# STM32U575 register map
File version: 1.4
CPU: CM33 r0p1, little endian, MPU, FPU, 4 interrupt priority bits
Registers are 32-bit, read-write, reset 0x0 unless marked. A register's access mark holds for its fields unless they carry their own. Offsets are from the block's base; [hi:lo] are bit positions; {n}, {i} and the like mark numbered series.

## ICache
Base 0x40030400
Same registers: SEC_ICache 0x50030400
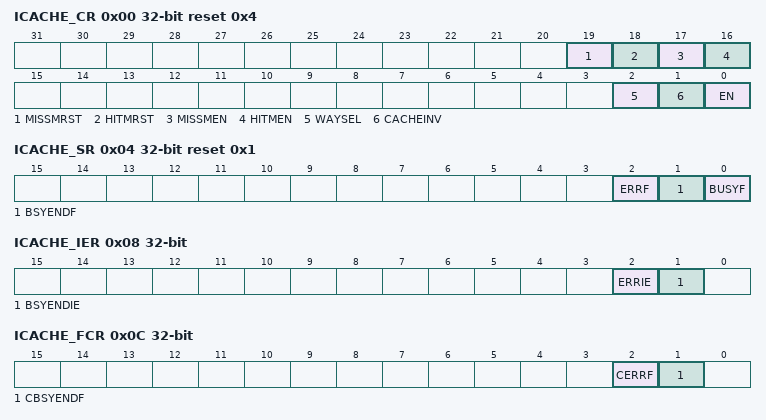
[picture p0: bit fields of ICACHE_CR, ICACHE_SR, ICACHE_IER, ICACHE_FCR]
0x00 ICACHE_CR access per field reset 0x4 — ICACHE control register
  [19] MISSMRST rw, [18] HITMRST rw, [17] MISSMEN rw, [16] HITMEN rw, [2] WAYSEL rw, [1] CACHEINV wo, [0] EN rw
0x04 ICACHE_SR ro reset 0x1 — ICACHE status register
  [2] ERRF, [1] BSYENDF, [0] BUSYF
0x08 ICACHE_IER — ICACHE interrupt enable register
  [2] ERRIE, [1] BSYENDIE
0x0C ICACHE_FCR wo — ICACHE flag clear register
  [2] CERRF, [1] CBSYENDF
0x10 ICACHE_HMONR ro — ICACHE hit monitor register
  [31:0] HITMON
0x14 ICACHE_MMONR ro — ICACHE miss monitor register
  [15:0] MISSMON
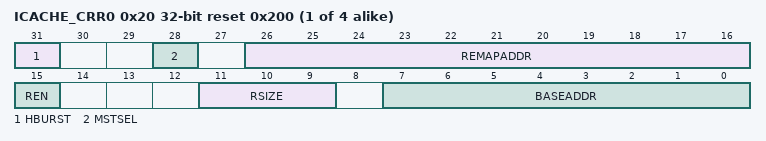
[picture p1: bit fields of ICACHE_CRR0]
{0x20+4i} ICACHE_CRR{i} reset 0x200 (i=0..3) — ICACHE region configuration register
  [31] HBURST, [28] MSTSEL, [26:16] REMAPADDR, [15] REN, [11:9] RSIZE, [7:0] BASEADDR

## DCACHE
Base 0x40031400
Same registers: SEC_DCACHE 0x50031400
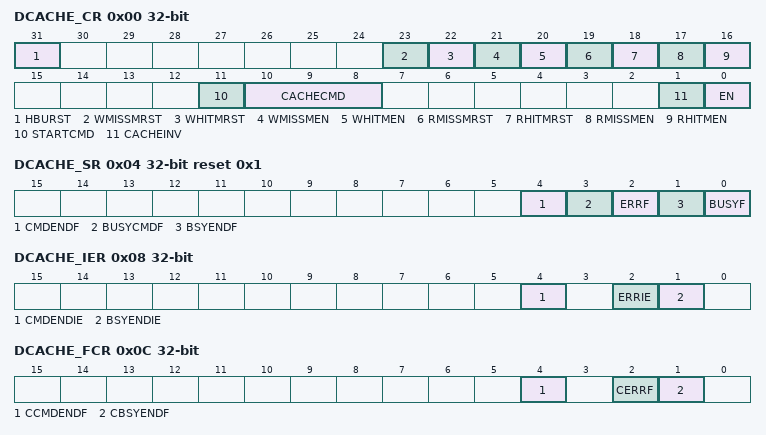
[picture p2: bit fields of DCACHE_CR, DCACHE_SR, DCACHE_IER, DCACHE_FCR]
0x00 DCACHE_CR access per field — DCACHE control register
  [31] HBURST rw, [23] WMISSMRST rw, [22] WHITMRST rw, [21] WMISSMEN rw, [20] WHITMEN rw, [19] RMISSMRST rw, [18] RHITMRST rw, [17] RMISSMEN rw, [16] RHITMEN rw, [11] STARTCMD wo, [10:8] CACHECMD rw, [1] CACHEINV wo, [0] EN rw
0x04 DCACHE_SR ro reset 0x1 — DCACHE status register
  [4] CMDENDF, [3] BUSYCMDF, [2] ERRF, [1] BSYENDF, [0] BUSYF
0x08 DCACHE_IER — DCACHE interrupt enable register
  [4] CMDENDIE, [2] ERRIE, [1] BSYENDIE
0x0C DCACHE_FCR wo — DCACHE flag clear register
  [4] CCMDENDF, [2] CERRF, [1] CBSYENDF
0x10 DCACHE_RHMONR ro — DCACHE read-hit monitor register
  [31:0] RHITMON
0x14 DCACHE_RMMONR ro — DCACHE read-miss monitor register
  [15:0] MRISSMON — RMISSMON
0x20 DCACHE_WHMONR ro — write-hit monitor register
  [31:0] WHITMON
0x24 DCACHE_WMMONR ro — write-miss monitor register
  [15:0] WMISSMON
0x28 DCACHE_CMDRSADDRR — command range start address register
  [31:0] CMDSTARTADDR
0x2C DCACHE_CMDREADDRR — command range start address register
  [31:0] CMDENDADDR

## IWDG — Independent watchdog
Base 0x40003000
Same registers: SEC_IWDG 0x50003000
0x00 KR wo — Key register
  [15:0] KEY — Key value (write only, read 0x0000)
0x04 PR — Prescaler register
  [3:0] PR — Prescaler divider
0x08 RLR reset 0xFFF — Reload register
  [11:0] RL — Watchdog counter reload value
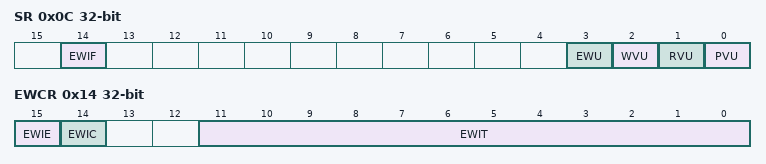
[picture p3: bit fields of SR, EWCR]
0x0C SR ro — Status register
  [14] EWIF — Watchdog Early interrupt flag
  [3] EWU — Watchdog interrupt comparator value update
  [2] WVU — Watchdog counter window value update
  [1] RVU — Watchdog counter reload value update
  [0] PVU — Watchdog prescaler value update
0x10 WINR reset 0xFFF — Window register
  [11:0] WIN — Watchdog counter window value
0x14 EWCR — IWDG early wakeup interrupt register
  [15] EWIE — Watchdog early interrupt enable
  [14] EWIC — Watchdog early interrupt acknowledge
  [11:0] EWIT — Watchdog counter window value

## GTZC1_MPCBB1
Base 0x40032C00
Same registers: SEC_GTZC1_MPCBB1 0x50032C00
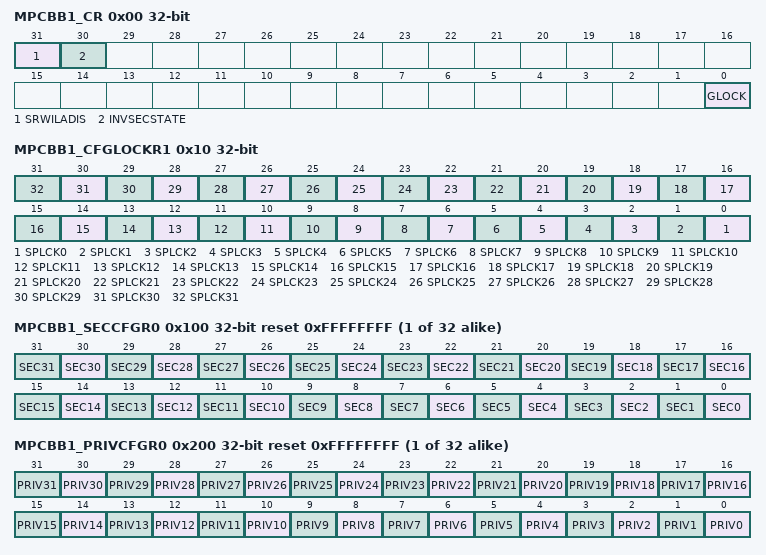
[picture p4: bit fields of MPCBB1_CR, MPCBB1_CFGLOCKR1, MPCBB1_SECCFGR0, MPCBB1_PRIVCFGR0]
0x00 MPCBB1_CR — MPCBB control register
  [31] SRWILADIS — secure read/write illegal access disable
  [30] INVSECSTATE — SRAMx clocks security state
  [0] GLOCK — lock the control register of the MPCBB until next reset
0x10 MPCBB1_CFGLOCKR1 — GTZC1 SRAMz MPCBB configuration lock register
  [n] SPLCK{n} (n=0..31)
{0x100+4i} MPCBB1_SECCFGR{i} reset 0xFFFFFFFF (i=0..31) — MPCBBx security configuration for super-block x register
  [n] SEC{n} (n=0..31)
{0x200+4i} MPCBB1_PRIVCFGR{i} reset 0xFFFFFFFF (i=0..31) — MPCBB privileged configuration for super-block x register
  [n] PRIV{n} (n=0..31)

## GTZC1_MPCBB2
Base 0x40033000
Same registers: SEC_GTZC1_MPCBB2 0x50033000
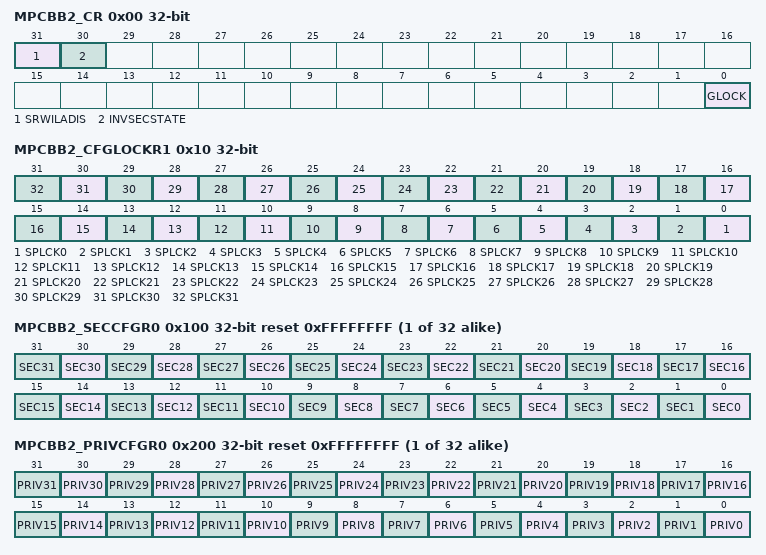
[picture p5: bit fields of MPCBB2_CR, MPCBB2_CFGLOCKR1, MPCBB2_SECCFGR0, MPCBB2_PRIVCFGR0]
0x00 MPCBB2_CR — MPCBB control register
  [31] SRWILADIS — secure read/write illegal access disable
  [30] INVSECSTATE — SRAMx clocks security state
  [0] GLOCK — lock the control register of the MPCBB until next reset
0x10 MPCBB2_CFGLOCKR1 — GTZC1 SRAMz MPCBB configuration lock register
  [n] SPLCK{n} (n=0..31)
{0x100+4i} MPCBB2_SECCFGR{i} reset 0xFFFFFFFF (i=0..31) — MPCBBx security configuration for super-block x register
  [n] SEC{n} (n=0..31)
{0x200+4i} MPCBB2_PRIVCFGR{i} reset 0xFFFFFFFF (i=0..31) — MPCBB privileged configuration for super-block x register
  [n] PRIV{n} (n=0..31)

## Notices in the file
Copyright (c) 2023 STMicroelectronics.
SPDX-License-Identifier: Apache-2.0
Licensed under the Apache License, Version 2.0 (the "License");
you may not use this file except in compliance with the License.
You may obtain a copy of the License at
http://www.apache.org/licenses/LICENSE-2.0
Unless required by applicable law or agreed to in writing, software
distributed under the License is distributed on an "AS IS" BASIS,
WITHOUT WARRANTIES OR CONDITIONS OF ANY KIND, either express or implied.
See the License for the specific language governing permissions and
limitations under the License.
